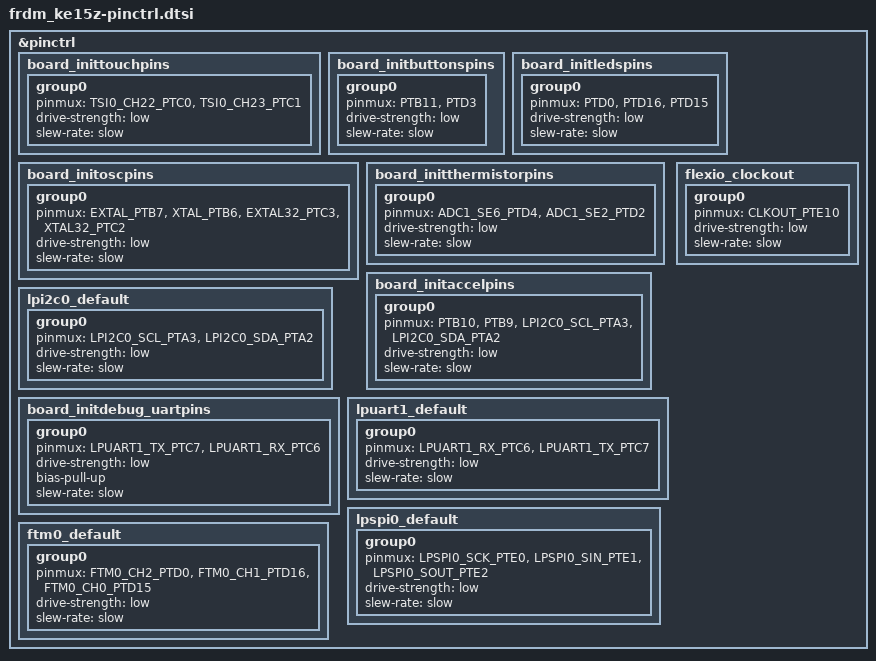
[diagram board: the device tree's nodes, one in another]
/*
 * NOTE: Autogenerated file by gen_board_pinctrl.py
 * for MKE15Z256VLL7/signal_configuration.xml
 *
 *
 */


#include <nxp/kinetis/MKE15Z256VLL7-pinctrl.h>

&pinctrl {
	/* Configures pin routing and optionally pin electrical features. */
	board_inittouchpins: board_inittouchpins {
		group0 {
			pinmux = <TSI0_CH22_PTC0>,
				<TSI0_CH23_PTC1>;
			drive-strength = "low";
			slew-rate = "slow";
		};
	};

	/* Configures pin routing and optionally pin electrical features. */
	board_initbuttonspins: board_initbuttonspins {
		group0 {
			pinmux = <PTB11>,
				<PTD3>;
			drive-strength = "low";
			slew-rate = "slow";
		};
	};

	/* Configures pin routing and optionally pin electrical features. */
	board_initledspins: board_initledspins {
		group0 {
			pinmux = <PTD0>,
				<PTD16>,
				<PTD15>;
			drive-strength = "low";
			slew-rate = "slow";
		};
	};

	/* Configures pin routing and optionally pin electrical features. */
	board_initoscpins: board_initoscpins {
		group0 {
			pinmux = <EXTAL_PTB7>,
				<XTAL_PTB6>,
				<EXTAL32_PTC3>,
				<XTAL32_PTC2>;
			drive-strength = "low";
			slew-rate = "slow";
		};
	};

	/* Configures pin routing and optionally pin electrical features. */
	board_initthermistorpins: board_initthermistorpins {
		group0 {
			pinmux = <ADC1_SE6_PTD4>,
				<ADC1_SE2_PTD2>;
			drive-strength = "low";
			slew-rate = "slow";
		};
	};

	/* Configures pin routing and optionally pin electrical features. */
	board_initaccelpins: board_initaccelpins {
		group0 {
			pinmux = <PTB10>,
				<PTB9>,
				<LPI2C0_SCL_PTA3>,
				<LPI2C0_SDA_PTA2>;
			drive-strength = "low";
			slew-rate = "slow";
		};
	};

	lpi2c0_default: lpi2c0_default {
		group0 {
			pinmux = <LPI2C0_SCL_PTA3>,
				<LPI2C0_SDA_PTA2>;
			drive-strength = "low";
			slew-rate = "slow";
		};
	};


	/* Configures pin routing and optionally pin electrical features. */
	board_initdebug_uartpins: board_initdebug_uartpins {
		group0 {
			pinmux = <LPUART1_TX_PTC7>,
				<LPUART1_RX_PTC6>;
			drive-strength = "low";
			bias-pull-up;
			slew-rate = "slow";
		};
	};

	lpuart1_default: lpuart1_default {
		group0 {
			pinmux = <LPUART1_RX_PTC6>,
				<LPUART1_TX_PTC7>;
			drive-strength = "low";
			slew-rate = "slow";
		};
	};

	lpspi0_default: lpspi0_default {
		group0 {
			pinmux = <LPSPI0_SCK_PTE0>,
				<LPSPI0_SIN_PTE1>,
				<LPSPI0_SOUT_PTE2>;
			drive-strength = "low";
			slew-rate = "slow";
		};
	};

	ftm0_default: ftm0_default {
		group0 {
			pinmux = <FTM0_CH2_PTD0>,
				<FTM0_CH1_PTD16>,
				<FTM0_CH0_PTD15>;
			drive-strength = "low";
			slew-rate = "slow";
		};

	};

	/* Route FLEXIO CLOCKOUT pin */
	flexio_clockout: flexio_clockout {
		group0 {
			pinmux = <CLKOUT_PTE10>;
			drive-strength = "low";
			slew-rate = "slow";
		};
	};
};
